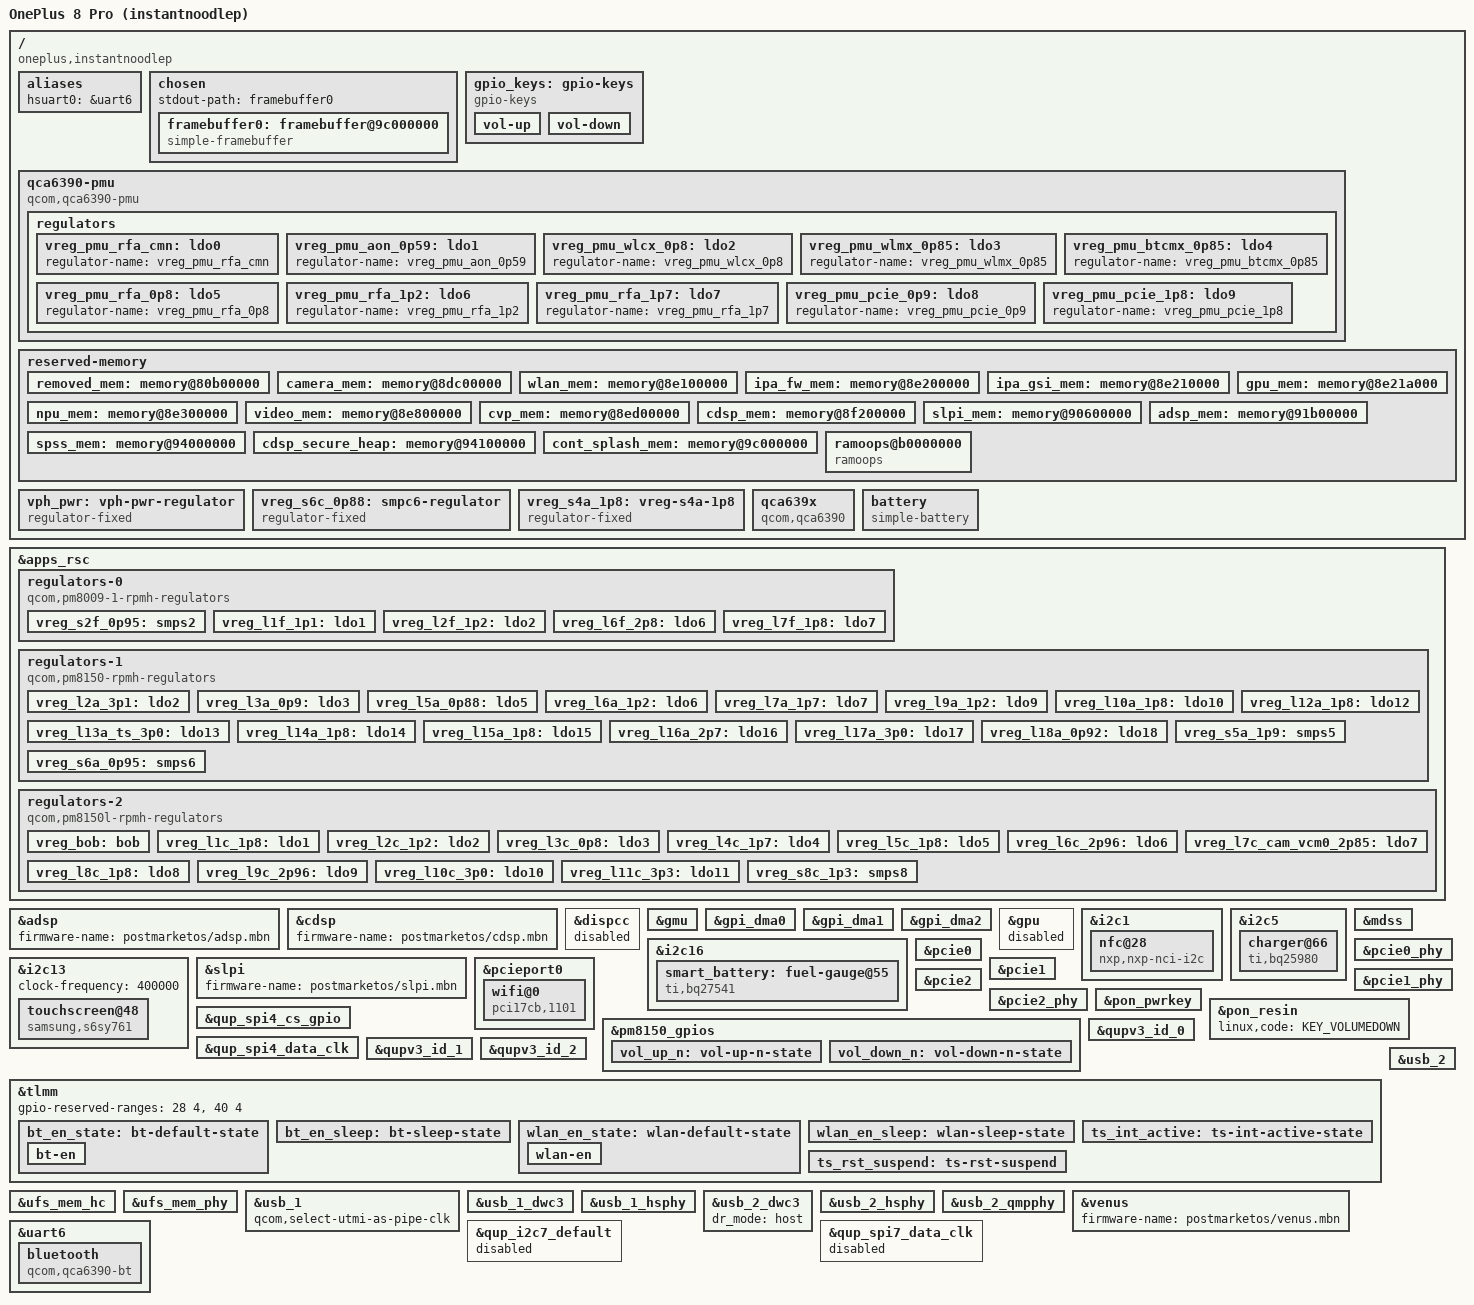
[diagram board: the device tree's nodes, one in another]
/dts-v1/;

#include <dt-bindings/gpio/gpio.h>
#include <dt-bindings/arm/qcom,ids.h>
#include <dt-bindings/regulator/qcom,rpmh-regulator.h>
#include <dt-bindings/phy/phy.h>
#include "sm8250.dtsi"
#include "pm8150.dtsi"
#include "pm8150b.dtsi"
#include "pm8150l.dtsi"
#include "pm8009.dtsi"

/*
 * Delete following upstream (sm8250.dtsi) reserved
 * memory mappings which are different in this device.
 */
/delete-node/ &removed_mem;
/delete-node/ &camera_mem;
/delete-node/ &wlan_mem;
/delete-node/ &ipa_fw_mem;
/delete-node/ &ipa_gsi_mem;
/delete-node/ &gpu_mem;
/delete-node/ &npu_mem;
/delete-node/ &video_mem;
/delete-node/ &cvp_mem;
/delete-node/ &cdsp_mem;
/delete-node/ &slpi_mem;
/delete-node/ &adsp_mem;
/delete-node/ &spss_mem;
/delete-node/ &cdsp_secure_heap;

/ {
	model = "OnePlus 8 Pro (instantnoodlep)";
	compatible = "oneplus,instantnoodlep", "qcom,kona", "qcom,sm8250";
	chassis-type = "handset";

	qcom,msm-id = <0x164 0x10000>, <0x164 0x20001>;
	qcom,board-id = <0x08 0x00>, <0x00 0x00>;

	aliases {
		hsuart0 = &uart6;
	};

	chosen {
		#address-cells = <2>;
		#size-cells = <2>;
		ranges;
		stdout-path = "framebuffer0";

		framebuffer0: framebuffer@9c000000 {
			compatible = "simple-framebuffer";
			reg = <0x0 0x9c000000 0x0 (1080 * 2376 * 4)>;
			width = <1080>;
			height = <2376>;
			stride = <(1080 * 4)>;
			format = "a8r8g8b8";
		};
	};

	gpio_keys: gpio-keys {
		compatible = "gpio-keys";

		vol-up {
			label = "Volume Up";
			gpios = <&pm8150_gpios 6 GPIO_ACTIVE_LOW>;
			linux,code = <KEY_VOLUMEUP>;
			debounce-interval = <15>;
			linux,can-disable;
			gpio-key,wakeup;
		};

		vol-down {
			label = "Volume Down";
			linux,code = <KEY_VOLUMEDOWN>;
			gpios = <&pm8150_gpios 7 GPIO_ACTIVE_LOW>;
			debounce-interval = <15>;
			linux,can-disable;
			gpio-key,wakeup;
		};
	};

	qca6390-pmu {
		compatible = "qcom,qca6390-pmu";

		pinctrl-names = "default";
		pinctrl-0 = <&bt_en_state>, <&wlan_en_state>;

		vddaon-supply = <&vreg_s6a_0p95>;
		vddpmu-supply = <&vreg_s2f_0p95>;
		vddrfa0p95-supply = <&vreg_s2f_0p95>;
		vddrfa1p3-supply = <&vreg_s8c_1p3>;
		vddrfa1p9-supply = <&vreg_s5a_1p9>;
		vddpcie1p3-supply = <&vreg_s8c_1p3>;
		vddpcie1p9-supply = <&vreg_s5a_1p9>;
		vddio-supply = <&vreg_s4a_1p8>;

		wlan-enable-gpios = <&tlmm 20 GPIO_ACTIVE_HIGH>;
		bt-enable-gpios = <&tlmm 21 GPIO_ACTIVE_HIGH>;

		regulators {
			vreg_pmu_rfa_cmn: ldo0 {
				regulator-name = "vreg_pmu_rfa_cmn";
			};

			vreg_pmu_aon_0p59: ldo1 {
				regulator-name = "vreg_pmu_aon_0p59";
			};

			vreg_pmu_wlcx_0p8: ldo2 {
				regulator-name = "vreg_pmu_wlcx_0p8";
			};

			vreg_pmu_wlmx_0p85: ldo3 {
				regulator-name = "vreg_pmu_wlmx_0p85";
			};

			vreg_pmu_btcmx_0p85: ldo4 {
				regulator-name = "vreg_pmu_btcmx_0p85";
			};

			vreg_pmu_rfa_0p8: ldo5 {
				regulator-name = "vreg_pmu_rfa_0p8";
			};

			vreg_pmu_rfa_1p2: ldo6 {
				regulator-name = "vreg_pmu_rfa_1p2";
			};

			vreg_pmu_rfa_1p7: ldo7 {
				regulator-name = "vreg_pmu_rfa_1p7";
			};

			vreg_pmu_pcie_0p9: ldo8 {
				regulator-name = "vreg_pmu_pcie_0p9";
			};

			vreg_pmu_pcie_1p8: ldo9 {
				regulator-name = "vreg_pmu_pcie_1p8";
			};
		};
	};
    
	reserved-memory {
		removed_mem: memory@80b00000 {
			reg = <0x0 0x80b00000 0x0 0xcd00000>;
			no-map;
		};

		camera_mem: memory@8dc00000 {
			reg = <0x0 0x8dc00000 0x0 0x500000>;
			no-map;
		};

		wlan_mem: memory@8e100000 {
			reg = <0x0 0x8e100000 0x0 0x100000>;
			no-map;
		};

		ipa_fw_mem: memory@8e200000 {
			reg = <0x0 0x8e200000 0x0 0x10000>;
			no-map;
		};

		ipa_gsi_mem: memory@8e210000 {
			reg = <0x0 0x8e210000 0x0 0xa000>;
			no-map;
		};

		gpu_mem: memory@8e21a000 {
			reg = <0x0 0x8e21a000 0x0 0x2000>;
			no-map;
		};

		npu_mem: memory@8e300000 {
			reg = <0x0 0x8e300000 0x0 0x500000>;
			no-map;
		};

		video_mem: memory@8e800000 {
			reg = <0x0 0x8e800000 0x0 0x500000>;
			no-map;
		};

		cvp_mem: memory@8ed00000 {
			reg = <0x0 0x8ed00000 0x0 0x500000>;
			no-map;
		};

		cdsp_mem: memory@8f200000 {
			reg = <0x0 0x8f200000 0x0 0x1400000>;
			no-map;
		};

		slpi_mem: memory@90600000 {
			reg = <0x0 0x90600000 0x0 0x1500000>;
			no-map;
		};

		adsp_mem: memory@91b00000 {
			reg = <0x00 0x91b00000 0x00 0x2500000>;
			no-map;
		};

		spss_mem: memory@94000000 {
			reg = <0x0 0x94000000 0x0 0x100000>;
			no-map;
		};

		cdsp_secure_heap: memory@94100000 {
			reg = <0x0 0x94100000 0x0 0x4600000>;
			no-map;
		};

		cont_splash_mem: memory@9c000000 {
				reg = <0x0 0x9c000000 0x0 0x2300000>;
				no-map;
		};

		ramoops@b0000000 {
			compatible = "ramoops";
			reg = <0x00 0xb0000000 0x00 0x400000>;
			record-size = <0x40000>;
			console-size = <0x40000>;
			ecc-size = <0x00>;
			no-map;
		};
	};

	vph_pwr: vph-pwr-regulator {
		compatible = "regulator-fixed";
		regulator-name = "vph_pwr";
		regulator-min-microvolt = <3700000>;
		regulator-max-microvolt = <3700000>;
	};

	vreg_s6c_0p88: smpc6-regulator {
		compatible = "regulator-fixed";
		regulator-name = "vreg_s6c_0p88";
		regulator-min-microvolt = <880000>;
		regulator-max-microvolt = <880000>;
		regulator-always-on;
		vin-supply = <&vph_pwr>;
	};

	vreg_s4a_1p8: vreg-s4a-1p8 {
		compatible = "regulator-fixed";
		regulator-name = "vreg_s4a_1p8";
		regulator-min-microvolt = <1800000>;
		regulator-max-microvolt = <1800000>;
		regulator-always-on;
	};

	qca639x: qca639x {
		compatible = "qcom,qca6390";
		#power-domain-cells = <0>;
 
		vddaon-supply = <&vreg_s6a_0p95>;
		vddpmu-supply = <&vreg_s2f_0p95>;
		vddrfa1-supply = <&vreg_s2f_0p95>;
		vddrfa2-supply = <&vreg_s8c_1p3>;
		vddrfa3-supply = <&vreg_s5a_1p9>;
		vddpcie1-supply = <&vreg_s8c_1p3>;
		vddpcie2-supply = <&vreg_s5a_1p9>;
		vddio-supply = <&vreg_s4a_1p8>;

		pinctrl-names = "default", "sleep";
		pinctrl-0 = <&wlan_en_state>;
		pinctrl-1 = <&wlan_en_sleep>;
 
		wlan-en-gpios = <&tlmm 20 GPIO_ACTIVE_HIGH>;
	};

	battery: battery {
		compatible = "simple-battery";

		charge-full-design-microamp-hours = <4410000>;
		energy-full-design-microwatt-hours = <17060000>;
		voltage-max-design-microvolt = <4350000>;
	};
};

&apps_rsc {
	regulators-0 {
		compatible = "qcom,pm8009-1-rpmh-regulators";
		qcom,pmic-id = "f";

		vdd-s1-supply = <&vph_pwr>;
		vdd-s2-supply = <&vph_pwr>;
		vdd-l2-supply = <&vreg_s8c_1p3>;
		vdd-l5-l6-supply = <&vreg_bob>;
		vdd-l7-supply = <&vreg_s4a_1p8>;

		vreg_s2f_0p95: smps2 {
			regulator-name = "vreg_s2f_0p95";
			regulator-min-microvolt = <900000>;
			regulator-max-microvolt = <952000>;
			regulator-initial-mode = <RPMH_REGULATOR_MODE_AUTO>;
		};

		vreg_l1f_1p1: ldo1 {
			regulator-name = "vreg_l1f_1p1";
			regulator-min-microvolt = <1104000>;
			regulator-max-microvolt = <1104000>;
			regulator-initial-mode = <RPMH_REGULATOR_MODE_HPM>;
		};

		vreg_l2f_1p2: ldo2 {
			regulator-name = "vreg_l2f_1p2";
			regulator-min-microvolt = <1200000>;
			regulator-max-microvolt = <1200000>;
			regulator-initial-mode = <RPMH_REGULATOR_MODE_HPM>;
		};

		vreg_l6f_2p8: ldo6 {
			regulator-name = "vreg_l6f_2p8";
			regulator-min-microvolt = <2800000>;
			regulator-max-microvolt = <2800000>;
			regulator-initial-mode = <RPMH_REGULATOR_MODE_HPM>;
		};

		vreg_l7f_1p8: ldo7 {
			regulator-name = "vreg_l7f_1p8";
			regulator-min-microvolt = <1800000>;
			regulator-max-microvolt = <1800000>;
			regulator-initial-mode = <RPMH_REGULATOR_MODE_HPM>;
		};
	};

	regulators-1 {
		compatible = "qcom,pm8150-rpmh-regulators";
		qcom,pmic-id = "a";

		vdd-s1-supply = <&vph_pwr>;
		vdd-s2-supply = <&vph_pwr>;
		vdd-s3-supply = <&vph_pwr>;
		vdd-s4-supply = <&vph_pwr>;
		vdd-s5-supply = <&vph_pwr>;
		vdd-s6-supply = <&vph_pwr>;
		vdd-s7-supply = <&vph_pwr>;
		vdd-s8-supply = <&vph_pwr>;
		vdd-s9-supply = <&vph_pwr>;
		vdd-s10-supply = <&vph_pwr>;
		vdd-l2-l10-supply = <&vreg_bob>;
		vdd-l3-l4-l5-l18-supply = <&vreg_s6a_0p95>;
		vdd-l6-l9-supply = <&vreg_s8c_1p3>;
		vdd-l7-l12-l14-l15-supply = <&vreg_s5a_1p9>;
		vdd-l13-l16-l17-supply = <&vreg_bob>;

		vreg_l2a_3p1: ldo2 {
			regulator-name = "vreg_l2a_3p1";
			regulator-min-microvolt = <3072000>;
			regulator-max-microvolt = <3072000>;
			regulator-initial-mode = <RPMH_REGULATOR_MODE_HPM>;
		};

		vreg_l3a_0p9: ldo3 {
			regulator-name = "vreg_l3a_0p9";
			regulator-min-microvolt = <928000>;
			regulator-max-microvolt = <932000>;
			regulator-initial-mode = <RPMH_REGULATOR_MODE_HPM>;
		};

		vreg_l5a_0p88: ldo5 {
			regulator-name = "vreg_l5a_0p88";
			regulator-min-microvolt = <880000>;
			regulator-max-microvolt = <880000>;
			regulator-initial-mode = <RPMH_REGULATOR_MODE_HPM>;
		};

		vreg_l6a_1p2: ldo6 {
			regulator-name = "vreg_l6a_1p2";
			regulator-min-microvolt = <1200000>;
			regulator-max-microvolt = <1200000>;
			regulator-initial-mode = <RPMH_REGULATOR_MODE_HPM>;
		};

		vreg_l7a_1p7: ldo7 {
			regulator-name = "vreg_l7a_1p7";
			regulator-min-microvolt = <1704000>;
			regulator-max-microvolt = <1800000>;
			regulator-initial-mode = <RPMH_REGULATOR_MODE_HPM>;
		};

		vreg_l9a_1p2: ldo9 {
			regulator-name = "vreg_l9a_1p2";
			regulator-min-microvolt = <1200000>;
			regulator-max-microvolt = <1200000>;
			regulator-initial-mode = <RPMH_REGULATOR_MODE_HPM>;
		};

		vreg_l10a_1p8: ldo10 {
			regulator-name = "vreg_l10a_1p8";
			regulator-min-microvolt = <1800000>;
			regulator-max-microvolt = <1800000>;
			regulator-initial-mode = <RPMH_REGULATOR_MODE_HPM>;
		};

		vreg_l12a_1p8: ldo12 {
			regulator-name = "vreg_l12a_1p8";
			regulator-min-microvolt = <1800000>;
			regulator-max-microvolt = <1800000>;
			regulator-initial-mode = <RPMH_REGULATOR_MODE_HPM>;
		};

		vreg_l13a_ts_3p0: ldo13 {
			regulator-name = "vreg_l13a_ts_3p0";
			regulator-min-microvolt = <3008000>;
			regulator-max-microvolt = <3008000>;
			regulator-initial-mode = <RPMH_REGULATOR_MODE_HPM>;
		};

		vreg_l14a_1p8: ldo14 {
			regulator-name = "vreg_l14a_1p8";
			regulator-min-microvolt = <1800000>;
			regulator-max-microvolt = <1880000>;
			regulator-initial-mode = <RPMH_REGULATOR_MODE_HPM>;
		};

		vreg_l15a_1p8: ldo15 {
			regulator-name = "vreg_l15a_1p8";
			regulator-min-microvolt = <1800000>;
			regulator-max-microvolt = <1800000>;
			regulator-initial-mode = <RPMH_REGULATOR_MODE_HPM>;
		};

		vreg_l16a_2p7: ldo16 {
			regulator-name = "vreg_l16a_2p7";
			regulator-min-microvolt = <2704000>;
			regulator-max-microvolt = <2960000>;
			regulator-initial-mode = <RPMH_REGULATOR_MODE_HPM>;
		};

		vreg_l17a_3p0: ldo17 {
			regulator-name = "vreg_l17a_3p0";
			regulator-min-microvolt = <2856000>;
			regulator-max-microvolt = <3008000>;
			regulator-initial-mode = <RPMH_REGULATOR_MODE_HPM>;
		};

		vreg_l18a_0p92: ldo18 {
			regulator-name = "vreg_l18a_0p92";
			regulator-min-microvolt = <800000>;
			regulator-max-microvolt = <912000>;
			regulator-initial-mode = <RPMH_REGULATOR_MODE_HPM>;
		};

		vreg_s5a_1p9: smps5 {
			regulator-name = "vreg_s5a_1p9";
			regulator-min-microvolt = <1904000>;
			regulator-max-microvolt = <2000000>;
			regulator-initial-mode = <RPMH_REGULATOR_MODE_HPM>;
		};


		vreg_s6a_0p95: smps6 {
			regulator-name = "vreg_s6a_0p95";
			regulator-min-microvolt = <920000>;
			regulator-max-microvolt = <1128000>;
			regulator-initial-mode = <RPMH_REGULATOR_MODE_HPM>;
		};
	};

	regulators-2 {
		compatible = "qcom,pm8150l-rpmh-regulators";
		qcom,pmic-id = "c";

		vdd-s1-supply = <&vph_pwr>;
		vdd-s2-supply = <&vph_pwr>;
		vdd-s3-supply = <&vph_pwr>;
		vdd-s4-supply = <&vph_pwr>;
		vdd-s5-supply = <&vph_pwr>;
		vdd-s6-supply = <&vph_pwr>;
		vdd-s7-supply = <&vph_pwr>;
		vdd-s8-supply = <&vph_pwr>;
		vdd-l1-l8-supply = <&vreg_s4a_1p8>;
		vdd-l2-l3-supply = <&vreg_s8c_1p3>;
		vdd-l4-l5-l6-supply = <&vreg_bob>;
		vdd-l7-l11-supply = <&vreg_bob>;
		vdd-l9-l10-supply = <&vreg_bob>;
		vdd-bob-supply = <&vph_pwr>;

		vreg_bob: bob {
			regulator-name = "vreg_bob";
			regulator-min-microvolt = <3008000>;
			regulator-max-microvolt = <4000000>;
			regulator-initial-mode = <RPMH_REGULATOR_MODE_AUTO>;
		};

		vreg_l1c_1p8: ldo1 {
			regulator-name = "vreg_l1c_1p8";
			regulator-min-microvolt = <1800000>;
			regulator-max-microvolt = <1800000>;
			regulator-initial-mode = <RPMH_REGULATOR_MODE_HPM>;
		};

		vreg_l2c_1p2: ldo2 {
			regulator-name = "vreg_l2c_1p2";
			regulator-min-microvolt = <1200000>;
			regulator-max-microvolt = <1200000>;
			regulator-initial-mode = <RPMH_REGULATOR_MODE_HPM>;
		};

		vreg_l3c_0p8: ldo3 {
			regulator-name = "vreg_l3c_0p8";
			regulator-min-microvolt = <800000>;
			regulator-max-microvolt = <800000>;
			regulator-initial-mode = <RPMH_REGULATOR_MODE_HPM>;
		};

		vreg_l4c_1p7: ldo4 {
			regulator-name = "vreg_l4c_1p7";
			regulator-min-microvolt = <1704000>;
			regulator-max-microvolt = <2928000>;
			regulator-initial-mode = <RPMH_REGULATOR_MODE_HPM>;
		};

		vreg_l5c_1p8: ldo5 {
			regulator-name = "vreg_l5c_1p8";
			regulator-min-microvolt = <1800000>;
			regulator-max-microvolt = <2928000>;
			regulator-initial-mode = <RPMH_REGULATOR_MODE_HPM>;
		};

		vreg_l6c_2p96: ldo6 {
			regulator-name = "vreg_l6c_2p96";
			regulator-min-microvolt = <1800000>;
			regulator-max-microvolt = <2960000>;
			regulator-initial-mode = <RPMH_REGULATOR_MODE_HPM>;
		};

		vreg_l7c_cam_vcm0_2p85: ldo7 {
			regulator-name = "vreg_l7c_cam_vcm0_2p85";
			regulator-min-microvolt = <2856000>;
			regulator-max-microvolt = <3104000>;
			regulator-initial-mode = <RPMH_REGULATOR_MODE_HPM>;
		};

		vreg_l8c_1p8: ldo8 {
			regulator-name = "vreg_l8c_1p8";
			regulator-min-microvolt = <1800000>;
			regulator-max-microvolt = <1800000>;
			regulator-initial-mode = <RPMH_REGULATOR_MODE_HPM>;
		};

		vreg_l9c_2p96: ldo9 {
			regulator-name = "vreg_l9c_2p96";
			regulator-min-microvolt = <2704000>;
			regulator-max-microvolt = <2960000>;
			regulator-initial-mode = <RPMH_REGULATOR_MODE_HPM>;
		};

		vreg_l10c_3p0: ldo10 {
			regulator-name = "vreg_l10c_3p0";
			regulator-min-microvolt = <3000000>;
			regulator-max-microvolt = <3000000>;
			regulator-initial-mode = <RPMH_REGULATOR_MODE_HPM>;
		};

		vreg_l11c_3p3: ldo11 {
			regulator-name = "vreg_l11c_3p3";
			regulator-min-microvolt = <3296000>;
			regulator-max-microvolt = <3296000>;
			regulator-initial-mode = <RPMH_REGULATOR_MODE_HPM>;
			regulator-always-on;
		};

		vreg_s8c_1p3: smps8 {
			regulator-name = "vreg_s8c_1p3";
			regulator-min-microvolt = <1352000>;
			regulator-max-microvolt = <1352000>;
			regulator-initial-mode = <RPMH_REGULATOR_MODE_HPM>;
		};
	};
};

&adsp {
	firmware-name = "postmarketos/adsp.mbn";
	status = "okay";
};

&cdsp {
	firmware-name = "postmarketos/cdsp.mbn";
	status = "okay";
};

&dispcc {
       status = "disabled";
};

&gmu {
	status = "okay";
};

&gpi_dma0 {
	status = "okay";
};

&gpi_dma1 {
	status = "okay";
};

&gpi_dma2 {
	status = "okay";
};

&gpu {
	status = "disabled";
};

&i2c1 {
    status = "okay";

    nfc@28 {
        compatible = "nxp,nxp-nci-i2c";
        reg = <0x28>;

        interrupt-parent = <&tlmm>;
        interrupts = <0x6f IRQ_TYPE_LEVEL_HIGH>;

        enable-gpios = <&tlmm 83 GPIO_ACTIVE_HIGH>,
                        <&tlmm 110 GPIO_ACTIVE_HIGH>;
    };
};

&i2c5 {
    status = "okay";

    charger@66 {
        compatible = "ti,bq25980";
        status = "ok";
        reg = <0x66>;
        interrupt-parent = <&tlmm>;
        interrupts = <0x0f 0x00>;
        monitored-battery = <&battery>;
    };
};

&i2c16 {
    status = "okay";

    smart_battery: fuel-gauge@55 {
        compatible = "ti,bq27541";
        reg = <0x55>;
        monitored-battery = <&battery>;
    };
};

&i2c13 {
	clock-frequency = <400000>;
	status = "okay";

	touchscreen@48 {
		compatible = "samsung,s6sy761";
		reg = <0x48>;
		interrupt-parent = <&tlmm>;
		interrupts = <0x27 0x2008>;

		vdd-supply = <&vreg_l13a_ts_3p0>;
		avdd-supply = <&vreg_l1c_1p8>;

		touchscreen-size-x = <1440>;
		touchscreen-size-y = <3168>;

		pinctrl-names = "default", "suspend";
		pinctrl-0 = <&ts_int_active>;
		pinctrl-1 = <&ts_rst_suspend>;
	};
};

&mdss {
	status = "okay";
};

&slpi {
	firmware-name = "postmarketos/slpi.mbn";
	status = "okay";
};


&pcie0 {
	status = "okay";
};

&pcie0_phy {
	status = "okay";
	vdda-phy-supply = <&vreg_l5a_0p88>;
	vdda-pll-supply = <&vreg_l9a_1p2>;
};

&pcieport0 {
	wifi@0 {
		compatible = "pci17cb,1101";
		reg = <0x10000 0x0 0x0 0x0 0x0>;

		vddrfacmn-supply = <&vreg_pmu_rfa_cmn>;
		vddaon-supply = <&vreg_pmu_aon_0p59>;
		vddwlcx-supply = <&vreg_pmu_wlcx_0p8>;
		vddwlmx-supply = <&vreg_pmu_wlmx_0p85>;
		vddrfa0p8-supply = <&vreg_pmu_rfa_0p8>;
		vddrfa1p2-supply = <&vreg_pmu_rfa_1p2>;
		vddrfa1p7-supply = <&vreg_pmu_rfa_1p7>;
		vddpcie0p9-supply = <&vreg_pmu_pcie_0p9>;
		vddpcie1p8-supply = <&vreg_pmu_pcie_1p8>;
	};
};

&pcie1 {
	status = "okay";
};

&pcie1_phy {
	vdda-phy-supply = <&vreg_l5a_0p88>;
	vdda-pll-supply = <&vreg_l9a_1p2>;
	status = "okay";
};

&pcie2 {
	status = "okay";
};

&pcie2_phy {
	vdda-phy-supply = <&vreg_l5a_0p88>;
	vdda-pll-supply = <&vreg_l9a_1p2>;
	status = "okay";
};

&pm8150_gpios {
	vol_up_n: vol-up-n-state {
		pins = "gpio6";
		function = "normal";
		power-source = <1>;
		input-enable;
		bias-pull-up;
	};

	vol_down_n: vol-down-n-state {
		pins = "gpio7";
		function = "normal";
		power-source = <1>;
		input-enable;
		bias-pull-up;
	};
};

&pon_pwrkey {
	status = "okay";
};

&pon_resin {
	linux,code = <KEY_VOLUMEDOWN>;
	status = "okay";
};

&qup_spi4_cs_gpio {
	drive-strength = <6>;
	bias-disable;
};

&qup_spi4_data_clk {
	drive-strength = <6>;
	bias-disable;
};

&qupv3_id_0 {
	status = "okay";
};

&qupv3_id_1 {
	status = "okay";
};

&qupv3_id_2 {
	status = "okay";
};

&tlmm {
	gpio-reserved-ranges = <28 4>, <40 4>;

	bt_en_state: bt-default-state {
		bt-en {
			pins = "gpio21";
			function = "gpio";

			drive-strength = <16>;
			output-low;
			bias-pull-up;
		};
	};

	bt_en_sleep: bt-sleep-state {
		pins = "gpio21";
		function = "gpio";

		drive-strength = <0x02>;
		output-low;
		bias-pull-down;
	};

	wlan_en_state: wlan-default-state {
		wlan-en {
			pins = "gpio20";
			function = "gpio";

			drive-strength = <16>;
			output-low;
			bias-pull-up;
		};
	};

	wlan_en_sleep: wlan-sleep-state {
		pins = "gpio20";
		function = "gpio";

		drive-strength = <16>;
		output-low;
		bias-pull-down;
	};

	ts_int_active: ts-int-active-state {
		pins = "gpio38", "gpio39";
		function = "gpio";
		drive-strength = <2>;
		bias-pull-up;
	};

	ts_rst_suspend: ts-rst-suspend {
		pins = "gpio38";
		function = "gpio";
		drive-strength = <0x02>;
		bias-pull-down;
	};
};

&ufs_mem_hc {
	vcc-supply = <&vreg_l17a_3p0>;
	vcc-max-microamp = <800000>;
	vccq-supply = <&vreg_l6a_1p2>;
	vccq-max-microamp = <800000>;
	vccq2-supply = <&vreg_s4a_1p8>;
	vccq2-max-microamp = <800000>;
	status = "okay";
};

&ufs_mem_phy {
	vdda-phy-supply = <&vreg_l5a_0p88>;
	vdda-pll-supply = <&vreg_l9a_1p2>;
	status = "okay";
};

&usb_1 {
	/* USB 2.0 only */
	qcom,select-utmi-as-pipe-clk;
	status = "okay";
};

&usb_1_dwc3 {
	dr_mode = "peripheral";
	maximum-speed = "high-speed";
	/* Remove USB3 phy */
	phys = <&usb_1_hsphy>;
	phy-names = "usb2-phy";
};

&usb_1_hsphy {
	vdda-pll-supply = <&vreg_l5a_0p88>;
	vdda18-supply = <&vreg_l12a_1p8>;
	vdda33-supply = <&vreg_l2a_3p1>;
	status = "okay";
};

&usb_2 {
	status = "okay";
};

&usb_2_dwc3 {
	dr_mode = "host";
};

&usb_2_hsphy {
	status = "okay";

	vdda-pll-supply = <&vreg_l5a_0p88>;
	vdda33-supply = <&vreg_l2a_3p1>;
	vdda18-supply = <&vreg_l12a_1p8>;
};

&usb_2_qmpphy {
	status = "okay";

	vdda-phy-supply = <&vreg_l9a_1p2>;
	vdda-pll-supply = <&vreg_l18a_0p92>;
};

&venus {
	firmware-name = "postmarketos/venus.mbn";
	status = "okay";
};


&uart6 {
	status = "okay";

	bluetooth {
		compatible = "qcom,qca6390-bt";

		vddrfacmn-supply = <&vreg_pmu_rfa_cmn>;
		vddaon-supply = <&vreg_pmu_aon_0p59>;
		vddbtcmx-supply = <&vreg_pmu_btcmx_0p85>;
		vddrfa0p8-supply = <&vreg_pmu_rfa_0p8>;
		vddrfa1p2-supply = <&vreg_pmu_rfa_1p2>;
		vddrfa1p7-supply = <&vreg_pmu_rfa_1p7>;
	};
};

&qup_i2c7_default {
	status = "disabled";
};

&qup_spi7_data_clk {
	status = "disabled";
};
